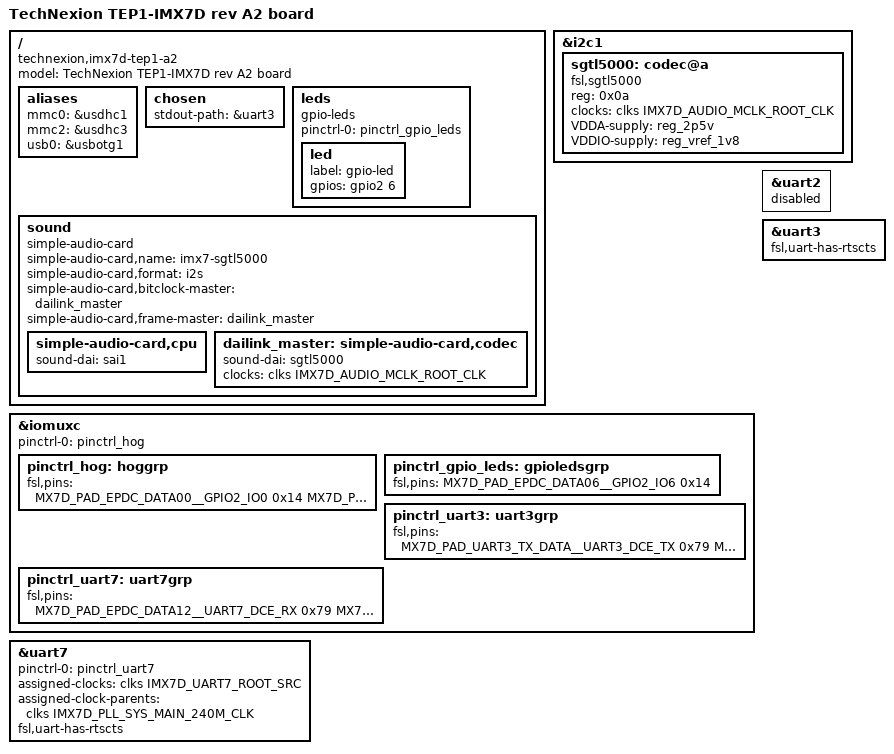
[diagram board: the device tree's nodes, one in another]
// SPDX-License-Identifier: (GPL-2.0+ OR MIT)
//
// Copyright 2017 NXP

#include "imx7d-tep1.dtsi"

/ {
	model = "TechNexion TEP1-IMX7D rev A2 board";
	compatible = "technexion,imx7d-tep1-a2", "fsl,imx7d";

	aliases {
		mmc0 = &usdhc1;
		mmc2 = &usdhc3;
		usb0 = &usbotg1;
	};

	chosen {
		stdout-path = &uart3;
	};

	leds {
		compatible = "gpio-leds";
		pinctrl-names = "default";
		pinctrl-0 = <&pinctrl_gpio_leds>;

		led {
			label = "gpio-led";
			gpios = <&gpio2 6 GPIO_ACTIVE_HIGH>;
		};
	};

	sound {
		compatible = "simple-audio-card";
		simple-audio-card,name = "imx7-sgtl5000";
		simple-audio-card,format = "i2s";
		simple-audio-card,bitclock-master = <&dailink_master>;
		simple-audio-card,frame-master = <&dailink_master>;
		simple-audio-card,cpu {
			sound-dai = <&sai1>;
		};

		dailink_master: simple-audio-card,codec {
			sound-dai = <&sgtl5000>;
			clocks = <&clks IMX7D_AUDIO_MCLK_ROOT_CLK>;
		};
	};
};

&i2c1 {
	sgtl5000: codec@a {
		#sound-dai-cells = <0>;
		reg = <0x0a>;
		compatible = "fsl,sgtl5000";
		clocks = <&clks IMX7D_AUDIO_MCLK_ROOT_CLK>;
		VDDA-supply = <&reg_2p5v>;
		VDDIO-supply = <&reg_vref_1v8>;
	};
};

&iomuxc {
	pinctrl-names = "default";
	pinctrl-0 = <&pinctrl_hog>;

	pinctrl_hog: hoggrp {
		fsl,pins = <
			MX7D_PAD_EPDC_DATA00__GPIO2_IO0		0x14
			MX7D_PAD_EPDC_DATA01__GPIO2_IO1		0x14
			MX7D_PAD_EPDC_DATA02__GPIO2_IO2		0x14
			MX7D_PAD_EPDC_DATA03__GPIO2_IO3		0x14
			MX7D_PAD_EPDC_DATA05__GPIO2_IO5		0x14
			MX7D_PAD_EPDC_DATA12__GPIO2_IO12	0x14
			MX7D_PAD_EPDC_DATA07__GPIO2_IO7		0x14
		>;
	};

	pinctrl_gpio_leds: gpioledsgrp {
		fsl,pins = <
			MX7D_PAD_EPDC_DATA06__GPIO2_IO6		0x14
		>;
	};

	pinctrl_uart3: uart3grp {
		fsl,pins = <
			MX7D_PAD_UART3_TX_DATA__UART3_DCE_TX	0x79
			MX7D_PAD_UART3_RX_DATA__UART3_DCE_RX	0x79
			MX7D_PAD_UART3_RTS_B__UART3_DCE_RTS	0x79
			MX7D_PAD_UART3_CTS_B__UART3_DCE_CTS	0x79
		>;
	};

	pinctrl_uart7: uart7grp {
		fsl,pins = <
			MX7D_PAD_EPDC_DATA12__UART7_DCE_RX	0x79
			MX7D_PAD_EPDC_DATA13__UART7_DCE_TX	0x79
			MX7D_PAD_EPDC_DATA14__UART7_DCE_RTS	0x79
			MX7D_PAD_EPDC_DATA15__UART7_DCE_CTS	0x79
		>;
	};
};

&uart2 {
	status = "disabled";
};

&uart3 {
	fsl,uart-has-rtscts;
};

&uart7 {
	pinctrl-names = "default";
	pinctrl-0 = <&pinctrl_uart7>;
	assigned-clocks = <&clks IMX7D_UART7_ROOT_SRC>;
	assigned-clock-parents = <&clks IMX7D_PLL_SYS_MAIN_240M_CLK>;
	fsl,uart-has-rtscts;
	status = "okay";
};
